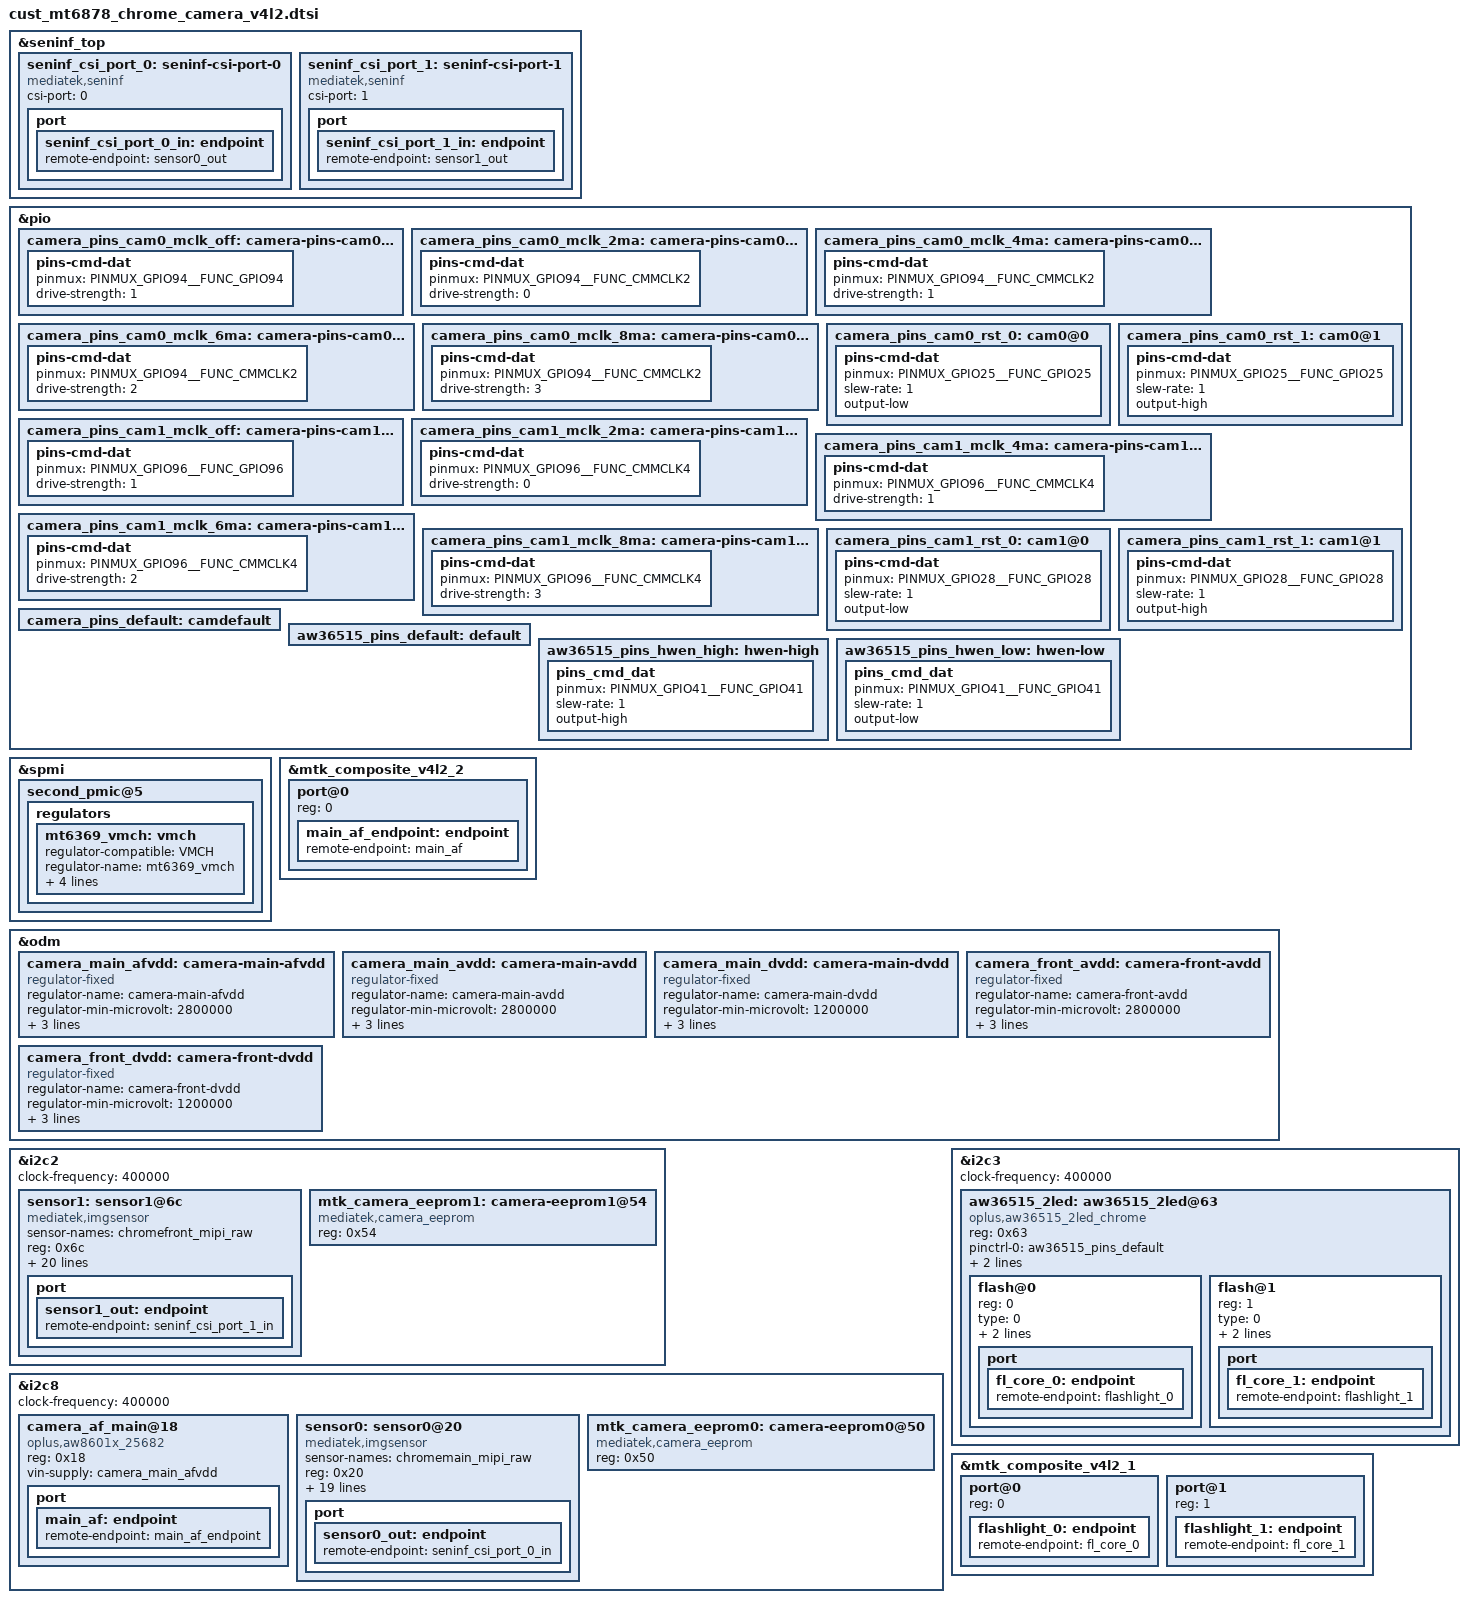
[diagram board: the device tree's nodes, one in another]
// SPDX-License-Identifier: GPL-2.0
/* Copyright (c) 2020 MediaTek Inc. */
#include <dt-bindings/clock/mt6878-clk.h>

&seninf_top {
		seninf_csi_port_0: seninf-csi-port-0 {
			compatible = "mediatek,seninf";
			csi-port = "0";
#if 0
			nvmem-cells = <&csi_efuse1>;
			nvmem-cell-names = "rg_csi";
#endif
			port {
				seninf_csi_port_0_in: endpoint {
					remote-endpoint = <&sensor0_out>;
				};
			};
		};

		seninf_csi_port_1: seninf-csi-port-1 {
			compatible = "mediatek,seninf";
			csi-port = "1";
#if 0
			nvmem-cells = <&csi_efuse2>;
			nvmem-cell-names = "rg_csi";
#endif
			port {
				seninf_csi_port_1_in: endpoint {
					remote-endpoint = <&sensor1_out>;
				};
			};
		};

};

/* CAMERA GPIO standardization */
&pio {
	camera_pins_cam0_mclk_off: camera-pins-cam0-mclk-off {
		pins-cmd-dat {
			pinmux = <PINMUX_GPIO94__FUNC_GPIO94>;
			drive-strength = <1>;
		};
	};
	camera_pins_cam0_mclk_2ma: camera-pins-cam0-mclk-2ma {
		pins-cmd-dat {
			pinmux = <PINMUX_GPIO94__FUNC_CMMCLK2>;
			drive-strength = <0>;
		};
	};
	camera_pins_cam0_mclk_4ma: camera-pins-cam0-mclk-4ma {
		pins-cmd-dat {
			pinmux = <PINMUX_GPIO94__FUNC_CMMCLK2>;
			drive-strength = <1>;
		};
	};
	camera_pins_cam0_mclk_6ma: camera-pins-cam0-mclk-6ma {
		pins-cmd-dat {
			pinmux = <PINMUX_GPIO94__FUNC_CMMCLK2>;
			drive-strength = <2>;
		};
	};
	camera_pins_cam0_mclk_8ma: camera-pins-cam0-mclk-8ma {
		pins-cmd-dat {
			pinmux = <PINMUX_GPIO94__FUNC_CMMCLK2>;
			drive-strength = <3>;
		};
	};
	camera_pins_cam0_rst_0: cam0@0 {
		pins-cmd-dat {
			pinmux = <PINMUX_GPIO25__FUNC_GPIO25>;
			slew-rate = <1>;
			output-low;
		};
	};
	camera_pins_cam0_rst_1: cam0@1 {
		pins-cmd-dat {
			pinmux = <PINMUX_GPIO25__FUNC_GPIO25>;
			slew-rate = <1>;
			output-high;
		};
	};

	camera_pins_cam1_mclk_off: camera-pins-cam1-mclk-off {
		pins-cmd-dat {
			pinmux = <PINMUX_GPIO96__FUNC_GPIO96>;
			drive-strength = <1>;
		};
	};
	camera_pins_cam1_mclk_2ma: camera-pins-cam1-mclk-2ma {
		pins-cmd-dat {
			pinmux = <PINMUX_GPIO96__FUNC_CMMCLK4>;
			drive-strength = <0>;
		};
	};
	camera_pins_cam1_mclk_4ma: camera-pins-cam1-mclk-4ma {
		pins-cmd-dat {
			pinmux = <PINMUX_GPIO96__FUNC_CMMCLK4>;
			drive-strength = <1>;
		};
	};
	camera_pins_cam1_mclk_6ma: camera-pins-cam1-mclk-6ma {
		pins-cmd-dat {
			pinmux = <PINMUX_GPIO96__FUNC_CMMCLK4>;
			drive-strength = <2>;
		};
	};
	camera_pins_cam1_mclk_8ma: camera-pins-cam1-mclk-8ma {
		pins-cmd-dat {
			pinmux = <PINMUX_GPIO96__FUNC_CMMCLK4>;
			drive-strength = <3>;
		};
	};
	camera_pins_cam1_rst_0: cam1@0 {
		pins-cmd-dat {
			pinmux = <PINMUX_GPIO28__FUNC_GPIO28>;
			slew-rate = <1>;
			output-low;
		};
	};
	camera_pins_cam1_rst_1: cam1@1 {
		pins-cmd-dat {
			pinmux = <PINMUX_GPIO28__FUNC_GPIO28>;
			slew-rate = <1>;
			output-high;
		};
	};
	camera_pins_default: camdefault {
	};
};
/* CAMERA GPIO end */

/*CAMERA mt6369-vmch*/
&spmi {
	second_pmic@5 {
		regulators {
			mt6369_vmch: vmch {
				regulator-compatible = "VMCH";
				regulator-name = "mt6369_vmch";
				regulator-min-microvolt = <1200000>;
				regulator-max-microvolt = <3500000>;
				regulator-enable-ramp-delay = <680>;
				regulator-allowed-modes = <0 2>;
			};
		};
	};
};

&mtk_composite_v4l2_2 {
	#address-cells = <1>;
	#size-cells = <0>;

	port@0 {
		reg = <0>;
		main_af_endpoint: endpoint {
			remote-endpoint = <&main_af>;
		};
	};
};

/* CAMERA GPIO fixed to regulator */
&odm {
	camera_main_afvdd: camera-main-afvdd {
		compatible = "regulator-fixed";
		regulator-name = "camera-main-afvdd";
		regulator-min-microvolt = <2800000>;
		regulator-max-microvolt = <2800000>;
		enable-active-high;
		gpio = <&pio 22 0x0>;
	};

	camera_main_avdd: camera-main-avdd {
		compatible = "regulator-fixed";
		regulator-name = "camera-main-avdd";
		regulator-min-microvolt = <2800000>;
		regulator-max-microvolt = <2800000>;
		enable-active-high;
		gpio = <&pio 27 0x0>;
	};

	camera_main_dvdd: camera-main-dvdd {
		compatible = "regulator-fixed";
		regulator-name = "camera-main-dvdd";
		regulator-min-microvolt = <1200000>;
		regulator-max-microvolt = <1200000>;
		enable-active-high;
		gpio = <&pio 42 0x0>;
	};

	camera_front_avdd: camera-front-avdd {
		compatible = "regulator-fixed";
		regulator-name = "camera-front-avdd";
		regulator-min-microvolt = <2800000>;
		regulator-max-microvolt = <2800000>;
		enable-active-high;
		gpio = <&pio 29 0x0>;
	};

	camera_front_dvdd: camera-front-dvdd {
		compatible = "regulator-fixed";
		regulator-name = "camera-front-dvdd";
		regulator-min-microvolt = <1200000>;
		regulator-max-microvolt = <1200000>;
		enable-active-high;
		gpio = <&pio 23 0x0>;
	};
};


&i2c2 {
	status = "okay";
	clock-frequency = <400000>;

	sensor1: sensor1@6c {
		compatible = "mediatek,imgsensor";
		sensor-names = "chromefront_mipi_raw";
		reg = <0x6c>;
		#reindex-to = <0>;
		#cust-aov-csi-clk = <312>;
		#thermal-sensor-cells = <0>;

		pinctrl-names = "mclk_off",
				"mclk_2mA",
				"mclk_4mA",
				"mclk_6mA",
				"mclk_8mA",
				"rst_low",
				"rst_high";

		pinctrl-0 = <&camera_pins_cam1_mclk_off>;
		pinctrl-1 = <&camera_pins_cam1_mclk_2ma>;
		pinctrl-2 = <&camera_pins_cam1_mclk_4ma>;
		pinctrl-3 = <&camera_pins_cam1_mclk_6ma>;
		pinctrl-4 = <&camera_pins_cam1_mclk_8ma>;
		pinctrl-5 = <&camera_pins_cam1_rst_0>;
		pinctrl-6 = <&camera_pins_cam1_rst_1>;

		dvdd-supply = <&camera_front_dvdd>;
		avdd-supply = <&camera_front_avdd>;
		dovdd-supply = <&mt6369_vant18>;

		clocks = <&topckgen_clk CLK_TOP_UVPLL192M_D32>,
			<&topckgen_clk CLK_TOP_UVPLL192M_D16>,
			<&topckgen_clk CLK_TOP_OSC_D20>,
			<&topckgen_clk CLK_TOP_UVPLL192M_D10>,
			<&topckgen_clk CLK_TOP_UVPLL192M_D8>,
			<&topckgen_clk CLK_TOP_TCK_26M_MX9>,
			<&topckgen_clk CLK_TOP_UNIVPLL_D6_D8>,
			<&topckgen_clk CLK_TOP_CAMTG5_SEL>;
		clock-names = "6", "12", "13", "19.2", "24", "26", "52", "mclk";


		status = "okay";
		port {
			sensor1_out: endpoint {
				remote-endpoint = <&seninf_csi_port_1_in>;
			};
		};
	};
    mtk_camera_eeprom1:camera-eeprom1@54 {
		compatible = "mediatek,camera_eeprom";
		reg = <0x54>;
		status = "okay";
	};
};

&i2c8 {
	status = "okay";
	clock-frequency = <400000>;

	camera_af_main@18 {
		compatible = "oplus,aw8601x_25682";
		reg = <0x18>;
		vin-supply = <&camera_main_afvdd>;
		port {
			main_af: endpoint {
				remote-endpoint = <&main_af_endpoint>;
			};
		};
	};
	sensor0: sensor0@20 {
		compatible = "mediatek,imgsensor";
		sensor-names = "chromemain_mipi_raw";
		reg = <0x20>;

		#thermal-sensor-cells = <0>;

		pinctrl-names = "mclk_off",
				"mclk_2mA",
				"mclk_4mA",
				"mclk_6mA",
				"mclk_8mA",
				"rst_low",
				"rst_high";

		pinctrl-0  = <&camera_pins_cam0_mclk_off>;
		pinctrl-1  = <&camera_pins_cam0_mclk_2ma>;
		pinctrl-2  = <&camera_pins_cam0_mclk_4ma>;
		pinctrl-3  = <&camera_pins_cam0_mclk_6ma>;
		pinctrl-4  = <&camera_pins_cam0_mclk_8ma>;
		pinctrl-5  = <&camera_pins_cam0_rst_0>;
		pinctrl-6  = <&camera_pins_cam0_rst_1>;

		afvdd-supply = <&camera_main_afvdd>;
		dvdd-supply = <&camera_main_dvdd>;
		avdd-supply = <&camera_main_avdd>;
		dovdd-supply = <&mt6369_vant18>;

		clocks = <&topckgen_clk CLK_TOP_UVPLL192M_D32>,
			<&topckgen_clk CLK_TOP_UVPLL192M_D16>,
			<&topckgen_clk CLK_TOP_OSC_D20>,
			<&topckgen_clk CLK_TOP_UVPLL192M_D10>,
			<&topckgen_clk CLK_TOP_UVPLL192M_D8>,
			<&topckgen_clk CLK_TOP_TCK_26M_MX9>,
			<&topckgen_clk CLK_TOP_UNIVPLL_D6_D8>,
			<&topckgen_clk CLK_TOP_CAMTG3_SEL>;
		clock-names = "6", "12", "13", "19.2", "24", "26", "52", "mclk";

		status = "okay";
		port {
			sensor0_out: endpoint {
				remote-endpoint = <&seninf_csi_port_0_in>;
			};
		};
	};

	mtk_camera_eeprom0:camera-eeprom0@50 {
		compatible = "mediatek,camera_eeprom";
		reg = <0x50>;
		status = "okay";
	};
};

&i2c3 {
	clock-frequency = <400000>;
	#address-cells = <1>;
	#size-cells = <0>;
	aw36515_2led:aw36515_2led@63 {
		compatible = "oplus,aw36515_2led_chrome";
		#address-cells = <1>;
		#size-cells = <0>;
		reg = <0x63>;
		#cooling-cells = <2>;
		pinctrl-names = "default", "hwen-high", "hwen-low";
		pinctrl-0 = <&aw36515_pins_default>;
		pinctrl-1 = <&aw36515_pins_hwen_high>;
		pinctrl-2 = <&aw36515_pins_hwen_low>;
		status = "okay";
		flash@0{
			reg = <0>;
			type = <0>;
			ct = <0>;
			part = <0>;
			port {
				fl_core_0: endpoint {
					remote-endpoint = <&flashlight_0>;
				};
			};
		};
		flash@1{
			reg = <1>;
			type = <0>;
			ct = <1>;
			part = <0>;
			port {
				fl_core_1: endpoint {
					remote-endpoint = <&flashlight_1>;
				};
			};
		};
	};
};

&pio {
	aw36515_pins_default: default {
	};

	aw36515_pins_hwen_high: hwen-high {
		pins_cmd_dat {
			pinmux = <PINMUX_GPIO41__FUNC_GPIO41>;// nobody use,just test
			slew-rate = <1>;
			output-high;
		};
	};

	aw36515_pins_hwen_low: hwen-low {
		pins_cmd_dat {
			pinmux = <PINMUX_GPIO41__FUNC_GPIO41>;
			slew-rate = <1>;
			output-low;
		};
	};
};

&mtk_composite_v4l2_1 {
	#address-cells = <1>;
	#size-cells = <0>;
	port@0 {
		reg = <0>;
		flashlight_0: endpoint {
			remote-endpoint = <&fl_core_0>;
		};
	};
	port@1 {
		reg = <1>;
		flashlight_1: endpoint {
			remote-endpoint = <&fl_core_1>;
		};
	};
};
